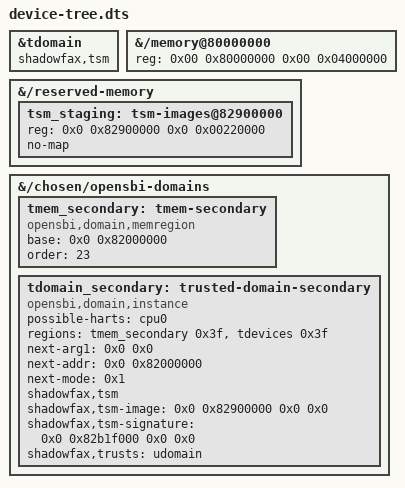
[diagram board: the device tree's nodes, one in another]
/dts-v1/;

/include/ "platform/generic/base.dtsi"
/include/ "platform/generic/default-domains.dtsi"

&tdomain {
	shadowfax,tsm;
};

/* The second trusted domain and its staging live above the generic map. */
&{/memory@80000000} {
	reg = <0x00 0x80000000 0x00 0x04000000>;
};

&{/reserved-memory} {
	tsm_staging: tsm-images@82900000 {
		reg = <0x0 0x82900000 0x0 0x00220000>;
		no-map;
	};
};

/*
 * Overlay nodes are appended after the generic untrusted domain. OpenSBI
 * therefore assigns domain 3 to this second trusted supervisor domain.
 */
&{/chosen/opensbi-domains} {
	tmem_secondary: tmem-secondary {
		compatible = "opensbi,domain,memregion";
		base = <0x0 0x82000000>;
		order = <23>;
	};

	tdomain_secondary: trusted-domain-secondary {
		compatible = "opensbi,domain,instance";
		possible-harts = <&cpu0>;
		regions = <&tmem_secondary 0x3f>, <&tdevices 0x3f>;
		next-arg1 = <0x0 0x0>;
		next-addr = <0x0 0x82000000>;
		next-mode = <0x1>;
		shadowfax,tsm;
		shadowfax,tsm-image = <0x0 0x82900000 0x0 0x0>;
		shadowfax,tsm-signature = <0x0 0x82b1f000 0x0 0x0>;
		shadowfax,trusts = <&udomain>;
	};
};
